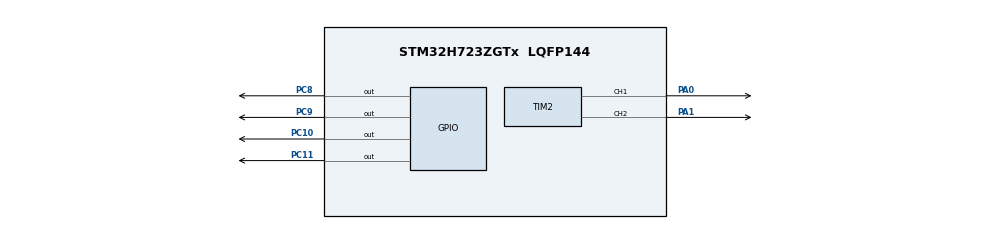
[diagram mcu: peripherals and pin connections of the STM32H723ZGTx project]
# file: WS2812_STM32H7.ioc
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CORTEX_M7.default_mode_Activation=1
Dma.Request0=TIM2_CH1
Dma.Request1=TIM2_CH2
Dma.Request2=TIM2_UP
Dma.TIM2_CH1.0.Direction=DMA_MEMORY_TO_PERIPH
Dma.TIM2_CH1.0.EventEnable=DISABLE
Dma.TIM2_CH1.0.FIFOMode=DMA_FIFOMODE_DISABLE
Dma.TIM2_CH1.0.Instance=DMA1_Stream0
Dma.TIM2_CH1.0.MemDataAlignment=DMA_MDATAALIGN_WORD
Dma.TIM2_CH1.0.MemInc=DMA_MINC_ENABLE
Dma.TIM2_CH1.0.Mode=DMA_CIRCULAR
Dma.TIM2_CH1.0.PeriphDataAlignment=DMA_PDATAALIGN_WORD
Dma.TIM2_CH1.0.PeriphInc=DMA_PINC_DISABLE
Dma.TIM2_CH1.0.Polarity=HAL_DMAMUX_REQ_GEN_RISING
Dma.TIM2_CH1.0.Priority=DMA_PRIORITY_VERY_HIGH
Dma.TIM2_CH1.0.RequestNumber=1
Dma.TIM2_CH1.0.SignalID=NONE
Dma.TIM2_CH1.0.SyncEnable=DISABLE
Dma.TIM2_CH1.0.SyncPolarity=HAL_DMAMUX_SYNC_NO_EVENT
Dma.TIM2_CH1.0.SyncRequestNumber=1
Dma.TIM2_CH1.0.SyncSignalID=NONE
Dma.TIM2_CH2.1.Direction=DMA_MEMORY_TO_PERIPH
Dma.TIM2_CH2.1.EventEnable=DISABLE
Dma.TIM2_CH2.1.FIFOMode=DMA_FIFOMODE_DISABLE
Dma.TIM2_CH2.1.Instance=DMA1_Stream1
Dma.TIM2_CH2.1.MemDataAlignment=DMA_MDATAALIGN_WORD
Dma.TIM2_CH2.1.MemInc=DMA_MINC_ENABLE
Dma.TIM2_CH2.1.Mode=DMA_CIRCULAR
Dma.TIM2_CH2.1.PeriphDataAlignment=DMA_PDATAALIGN_WORD
Dma.TIM2_CH2.1.PeriphInc=DMA_PINC_DISABLE
Dma.TIM2_CH2.1.Polarity=HAL_DMAMUX_REQ_GEN_RISING
Dma.TIM2_CH2.1.Priority=DMA_PRIORITY_VERY_HIGH
Dma.TIM2_CH2.1.RequestNumber=1
Dma.TIM2_CH2.1.SignalID=NONE
Dma.TIM2_CH2.1.SyncEnable=DISABLE
Dma.TIM2_CH2.1.SyncPolarity=HAL_DMAMUX_SYNC_NO_EVENT
Dma.TIM2_CH2.1.SyncRequestNumber=1
Dma.TIM2_CH2.1.SyncSignalID=NONE
Dma.TIM2_UP.2.Direction=DMA_MEMORY_TO_PERIPH
Dma.TIM2_UP.2.EventEnable=DISABLE
Dma.TIM2_UP.2.FIFOMode=DMA_FIFOMODE_DISABLE
Dma.TIM2_UP.2.Instance=DMA1_Stream2
Dma.TIM2_UP.2.MemDataAlignment=DMA_MDATAALIGN_WORD
Dma.TIM2_UP.2.MemInc=DMA_MINC_ENABLE
Dma.TIM2_UP.2.Mode=DMA_CIRCULAR
Dma.TIM2_UP.2.PeriphDataAlignment=DMA_PDATAALIGN_WORD
Dma.TIM2_UP.2.PeriphInc=DMA_PINC_DISABLE
Dma.TIM2_UP.2.Polarity=HAL_DMAMUX_REQ_GEN_RISING
Dma.TIM2_UP.2.Priority=DMA_PRIORITY_VERY_HIGH
Dma.TIM2_UP.2.RequestNumber=1
Dma.TIM2_UP.2.SignalID=NONE
Dma.TIM2_UP.2.SyncEnable=DISABLE
Dma.TIM2_UP.2.SyncPolarity=HAL_DMAMUX_SYNC_NO_EVENT
Dma.TIM2_UP.2.SyncRequestNumber=1
Dma.TIM2_UP.2.SyncSignalID=NONE
Mcu.Family=STM32H7
Mcu.Name=STM32H723ZGTx
Mcu.Package=LQFP144
NUCLEO-H723ZG.BUTTON=1
NUCLEO-H723ZG.LD1=true
NUCLEO-H723ZG.LD2=true
NUCLEO-H723ZG.LD3=true
NUCLEO-H723ZG.VCP=true
NVIC.DMA1_Stream0_IRQn=true\:0\:0\:false\:false\:true\:false\:true\:true
NVIC.DMA1_Stream1_IRQn=true\:0\:0\:false\:false\:true\:false\:true\:true
NVIC.DMA1_Stream2_IRQn=true\:0\:0\:false\:false\:true\:false\:true\:true
NVIC.EXTI15_10_IRQn=true\:0\:0\:false\:false\:true\:false\:true\:true
NVIC.PriorityGroup=NVIC_PRIORITYGROUP_4
NVIC.TIM2_IRQn=true\:0\:0\:false\:false\:true\:true\:true\:true
PA0.Signal=S_TIM2_CH1_ETR
PA1.Signal=S_TIM2_CH2
PA13(JTMS/SWDIO).GPIO_Label=SWDIO
PA13(JTMS/SWDIO).Signal=DEBUG_JTMS-SWDIO
PA14(JTCK/SWCLK).GPIO_Label=SWCLK
PA14(JTCK/SWCLK).Signal=DEBUG_JTCK-SWCLK
PC10.Signal=GPIO_Output
PC11.Signal=GPIO_Output
PC14-OSC32_IN.Signal=RCC_OSC32_IN
PC15-OSC32_OUT.Signal=RCC_OSC32_OUT
PC8.Signal=GPIO_Output
PC9.Signal=GPIO_Output
PD8.Signal=USART3_TX
PD9.Signal=USART3_RX
ProjectManager.HeapSize=0x200
ProjectManager.StackSize=0x400
ProjectManager.TargetToolchain=CMake
RCC.ADCFreq_Value=608000000
RCC.APB1Freq_Value=100000000
RCC.APB2Freq_Value=100000000
RCC.APB3Freq_Value=100000000
RCC.APB4Freq_Value=100000000
RCC.CortexFreq_Value=400000000
RCC.D1PPRE=RCC_APB3_DIV2
RCC.D2PPRE1=RCC_APB1_DIV2
RCC.D2PPRE2=RCC_APB2_DIV2
RCC.D3PPRE=RCC_APB4_DIV2
RCC.DIVM1=4
RCC.DIVM2=1
RCC.DIVN1=25
RCC.DIVN2=19
RCC.DIVP1=1
RCC.DIVQ1=4
RCC.HCLKFreq_Value=200000000
RCC.HPRE=RCC_HCLK_DIV2
RCC.HSE_VALUE=8000000
RCC.PLLFRACN=0
RCC.SYSCLKFreq_VALUE=400000000
RCC.SYSCLKSource=RCC_SYSCLKSOURCE_PLLCLK
RCC.USBCLockSelection=RCC_USBCLKSOURCE_HSI48
RCC.USBFreq_Value=48000000
SH.S_TIM2_CH1_ETR.0=TIM2_CH1,PWM Generation1 CH1
SH.S_TIM2_CH2.0=TIM2_CH2,PWM Generation2 CH2
TIM2.AutoReloadPreload=TIM_AUTORELOAD_PRELOAD_ENABLE
TIM2.Channel-PWM\ Generation1\ CH1=TIM_CHANNEL_1
TIM2.Channel-PWM\ Generation2\ CH2=TIM_CHANNEL_2
VP_MEMORYMAP_VS_MEMORYMAP.Mode=CurAppReg
VP_NUCLEO-H723ZG_VS_BSP_COMMON.Mode=COMMON
board=NUCLEO-H723ZG

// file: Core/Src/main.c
/* USER CODE BEGIN Header */
/**
  ******************************************************************************
  * @file           : main.c
  * @brief          : Main program body
  ******************************************************************************
  * @attention
  *
  * Copyright (c) 2026 STMicroelectronics.
  * All rights reserved.
  *
  * This software is licensed under terms that can be found in the LICENSE file
  * in the root directory of this software component.
  * If no LICENSE file comes with this software, it is provided AS-IS.
  *
  ******************************************************************************
  */
/* USER CODE END Header */
#include "main.h"
#include "dma.h"
#include "tim.h"
#include "gpio.h"

/* USER CODE BEGIN Includes */
#include "visEffect.h"
/* USER CODE END Includes */

COM_InitTypeDef BspCOMInit;

void SystemClock_Config(void);
static void MPU_Config(void);

int main(void) {

  /* USER CODE BEGIN 1 */

  // Enable the CPU instruction cache to speed up code execution from Flash.
  SCB_EnableICache();

  /* USER CODE END 1 */

  /* MPU Configuration--------------------------------------------------------*/
  MPU_Config();

  /* MCU Configuration--------------------------------------------------------*/

  /* Reset of all peripherals, Initializes the Flash interface and the Systick.
   */
  HAL_Init();

  /* Configure the system clock */
  SystemClock_Config();

  /* Initialize all configured peripherals */
  MX_GPIO_Init();
  MX_DMA_Init();
  MX_TIM2_Init();
  /* USER CODE BEGIN 2 */
  // Initialize WS2812 driver + visual effects (configures TIM2/DMA/GPIO usage)
  visInit();
  /* USER CODE END 2 */

  /* Initialize leds */
  BSP_LED_Init(LED_GREEN);
  BSP_LED_Init(LED_YELLOW);
  BSP_LED_Init(LED_RED);

  /* Initialize USER push-button, will be used to trigger an interrupt each time
   * it's pressed.*/
  BSP_PB_Init(BUTTON_USER, BUTTON_MODE_EXTI);

  /* Initialize COM1 port (115200, 8 bits (7-bit data + 1 stop bit), no parity
   */
  BspCOMInit.BaudRate = 115200;
  BspCOMInit.WordLength = COM_WORDLENGTH_8B;
  BspCOMInit.StopBits = COM_STOPBITS_1;
  BspCOMInit.Parity = COM_PARITY_NONE;
  BspCOMInit.HwFlowCtl = COM_HWCONTROL_NONE;
  if (BSP_COM_Init(COM1, &BspCOMInit) != BSP_ERROR_NONE) {
    Error_Handler();
  }

  /* Infinite loop */
  while (1) {

    /* USER CODE BEGIN 3 */
    // Animate effects and push frames to the WS2812 strips
    visHandle();
  }
  /* USER CODE END 3 */
}

void SystemClock_Config(void) {
  RCC_OscInitTypeDef RCC_OscInitStruct = {0};
  RCC_ClkInitTypeDef RCC_ClkInitStruct = {0};

  /** Supply configuration update enable
  */
  HAL_PWREx_ConfigSupply(PWR_LDO_SUPPLY);

  /** Configure the main internal regulator output voltage
  */
  __HAL_PWR_VOLTAGESCALING_CONFIG(PWR_REGULATOR_VOLTAGE_SCALE1);

  while (!__HAL_PWR_GET_FLAG(PWR_FLAG_VOSRDY)) {
  }

  /** Initializes the RCC Oscillators according to the specified parameters
  * in the RCC_OscInitTypeDef structure.
  */
  RCC_OscInitStruct.OscillatorType = RCC_OSCILLATORTYPE_HSI;
  RCC_OscInitStruct.HSIState = RCC_HSI_DIV1;
  RCC_OscInitStruct.HSICalibrationValue = 64;
  RCC_OscInitStruct.PLL.PLLState = RCC_PLL_ON;
  RCC_OscInitStruct.PLL.PLLSource = RCC_PLLSOURCE_HSI;
  RCC_OscInitStruct.PLL.PLLM = 4;
  RCC_OscInitStruct.PLL.PLLN = 25;
  RCC_OscInitStruct.PLL.PLLP = 1;
  RCC_OscInitStruct.PLL.PLLQ = 4;
  RCC_OscInitStruct.PLL.PLLR = 2;
  RCC_OscInitStruct.PLL.PLLRGE = RCC_PLL1VCIRANGE_3;
  RCC_OscInitStruct.PLL.PLLVCOSEL = RCC_PLL1VCOWIDE;
  RCC_OscInitStruct.PLL.PLLFRACN = 0;
  if (HAL_RCC_OscConfig(&RCC_OscInitStruct) != HAL_OK) {
    Error_Handler();
  }

  /** Initializes the CPU, AHB and APB buses clocks
  */
  RCC_ClkInitStruct.ClockType = RCC_CLOCKTYPE_HCLK | RCC_CLOCKTYPE_SYSCLK |
                                RCC_CLOCKTYPE_PCLK1 | RCC_CLOCKTYPE_PCLK2 |
                                RCC_CLOCKTYPE_D3PCLK1 | RCC_CLOCKTYPE_D1PCLK1;
  RCC_ClkInitStruct.SYSCLKSource = RCC_SYSCLKSOURCE_PLLCLK;
  RCC_ClkInitStruct.SYSCLKDivider = RCC_SYSCLK_DIV1;
  RCC_ClkInitStruct.AHBCLKDivider = RCC_HCLK_DIV2;
  RCC_ClkInitStruct.APB3CLKDivider = RCC_APB3_DIV2;
  RCC_ClkInitStruct.APB1CLKDivider = RCC_APB1_DIV2;
  RCC_ClkInitStruct.APB2CLKDivider = RCC_APB2_DIV2;
  RCC_ClkInitStruct.APB4CLKDivider = RCC_APB4_DIV2;

  if (HAL_RCC_ClockConfig(&RCC_ClkInitStruct, FLASH_LATENCY_2) != HAL_OK) {
    Error_Handler();
  }
}

/* MPU Configuration */

void MPU_Config(void) {
  MPU_Region_InitTypeDef MPU_InitStruct = {0};

  /* Disables the MPU */
  HAL_MPU_Disable();

  /** Initializes and configures the Region and the memory to be protected
  */
  MPU_InitStruct.Enable = MPU_REGION_ENABLE;
  MPU_InitStruct.Number = MPU_REGION_NUMBER0;
  MPU_InitStruct.BaseAddress = 0x0;
  MPU_InitStruct.Size = MPU_REGION_SIZE_4GB;
  MPU_InitStruct.SubRegionDisable = 0x87;
  MPU_InitStruct.TypeExtField = MPU_TEX_LEVEL0;
  MPU_InitStruct.AccessPermission = MPU_REGION_NO_ACCESS;
  MPU_InitStruct.DisableExec = MPU_INSTRUCTION_ACCESS_DISABLE;
  MPU_InitStruct.IsShareable = MPU_ACCESS_SHAREABLE;
  MPU_InitStruct.IsCacheable = MPU_ACCESS_NOT_CACHEABLE;
  MPU_InitStruct.IsBufferable = MPU_ACCESS_NOT_BUFFERABLE;

  HAL_MPU_ConfigRegion(&MPU_InitStruct);
  /* Enables the MPU */
  HAL_MPU_Enable(MPU_PRIVILEGED_DEFAULT);
}

void Error_Handler(void) {
  __disable_irq();
  while (1) {
  }
}
#ifdef USE_FULL_ASSERT
/**
  * @brief  Reports the name of the source file and the source line number
  *         where the assert_param error has occurred.
  * @param  file: pointer to the source file name
  * @param  line: assert_param error line source number
  * @retval None
  */
void assert_failed(uint8_t *file, uint32_t line) {
  /* USER CODE BEGIN 6 */
  /* User can add his own implementation to report the file name and line
     number,
     ex: printf("Wrong parameters value: file %s on line %d\r\n", file, line) */
  /* USER CODE END 6 */
}
#endif /* USE_FULL_ASSERT */
